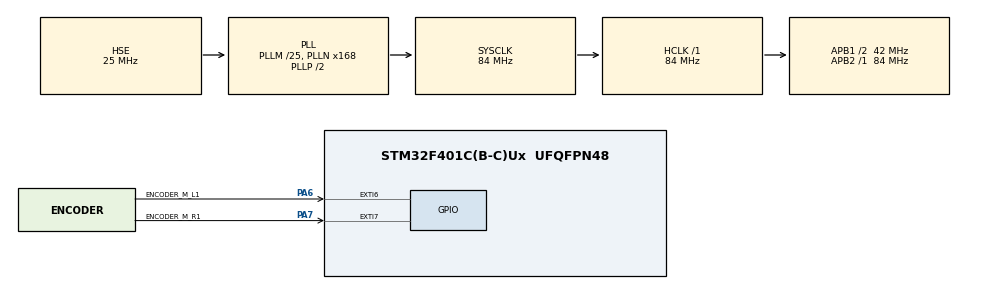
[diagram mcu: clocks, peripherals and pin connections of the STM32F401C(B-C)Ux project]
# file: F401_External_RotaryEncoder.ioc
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Mcu.Family=STM32F4
Mcu.Name=STM32F401C(B-C)Ux
Mcu.Package=UFQFPN48
NVIC.EXTI9_5_IRQn=true\:0\:0\:false\:false\:true\:true\:true\:true
NVIC.PriorityGroup=NVIC_PRIORITYGROUP_4
PA13.Mode=Serial_Wire
PA13.Signal=SYS_JTMS-SWDIO
PA14.Mode=Serial_Wire
PA14.Signal=SYS_JTCK-SWCLK
PA6.GPIO_Label=ENCODER_M_L1
PA6.GPIO_ModeDefaultEXTI=GPIO_MODE_IT_RISING_FALLING
PA6.GPIO_PuPd=GPIO_NOPULL
PA6.Signal=GPXTI6
PA7.GPIO_Label=ENCODER_M_R1
PA7.GPIO_ModeDefaultEXTI=GPIO_MODE_IT_RISING_FALLING
PA7.GPIO_PuPd=GPIO_NOPULL
PA7.Signal=GPXTI7
PH0\ -\ OSC_IN.Mode=HSE-External-Oscillator
PH0\ -\ OSC_IN.Signal=RCC_OSC_IN
PH1\ -\ OSC_OUT.Mode=HSE-External-Oscillator
PH1\ -\ OSC_OUT.Signal=RCC_OSC_OUT
ProjectManager.HeapSize=0x200
ProjectManager.StackSize=0x400
ProjectManager.TargetToolchain=STM32CubeIDE
RCC.48MHZClocksFreq_Value=42000000
RCC.AHBFreq_Value=84000000
RCC.APB1CLKDivider=RCC_HCLK_DIV2
RCC.APB1Freq_Value=42000000
RCC.APB1TimFreq_Value=84000000
RCC.APB2Freq_Value=84000000
RCC.APB2TimFreq_Value=84000000
RCC.CortexFreq_Value=84000000
RCC.HCLKFreq_Value=84000000
RCC.HSE_VALUE=25000000
RCC.HSI_VALUE=16000000
RCC.LSE_VALUE=32768
RCC.PLLM=25
RCC.PLLN=168
RCC.PLLSourceVirtual=RCC_PLLSOURCE_HSE
RCC.SYSCLKFreq_VALUE=84000000
RCC.SYSCLKSource=RCC_SYSCLKSOURCE_PLLCLK
RCC.VCOOutputFreq_Value=168000000
board=custom

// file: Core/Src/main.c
/* USER CODE BEGIN Header */
/**
 ******************************************************************************
 * @file           : main.c
 * @brief          : Main program body
 ******************************************************************************
 * @attention
 *
 * Copyright (c) 2024 STMicroelectronics.
 * All rights reserved.
 *
 * This software is licensed under terms that can be found in the LICENSE file
 * in the root directory of this software component.
 * If no LICENSE file comes with this software, it is provided AS-IS.
 *
 ******************************************************************************
 */
/* USER CODE END Header */
#include "main.h"
#include "gpio.h"

/* USER CODE BEGIN PV */

#define ENCODER_M_L1_Pin GPIO_PIN_6
#define ENCODER_M_R1_Pin GPIO_PIN_7
#define ENCODER_M_L1_GPIO_Port GPIOA
#define ENCODER_M_R1_GPIO_Port GPIOA
int encoder1;
int encoder2;
int counter = 0;
int last_encoder1 = 0;
int last_encoder2 = 0;

/* USER CODE END PV */

void SystemClock_Config(void);
/* USER CODE BEGIN PFP */

/* EXTERNAL ENTERRUPT */

void HAL_GPIO_EXTI_Callback(uint16_t GPIO_Pin) {
	if (GPIO_Pin == ENCODER_M_L1_Pin || ENCODER_M_R1_Pin) {
		encoder1 = HAL_GPIO_ReadPin(ENCODER_M_L1_GPIO_Port, ENCODER_M_L1_Pin);
		encoder2 = HAL_GPIO_ReadPin(ENCODER_M_R1_GPIO_Port, ENCODER_M_R1_Pin);
	}
}

/* USER CODE END PFP */

int main(void) {
	/* USER CODE BEGIN 1 */

	/* READ ENCODER */

	void encoder() {
		if (encoder1 != last_encoder1) {
			last_encoder1 = encoder1;
			if (encoder1 == 0) {
				if (encoder2 == 1) {
					counter++;
				} else {
					counter--;
				}
			} else {
				if (encoder2 == 0) {
					counter++;
				} else {
					counter--;
				}
			}
		}
		if (encoder2 != last_encoder2) {
			last_encoder2 = encoder2;
			if (encoder2 == 1) {
				if (encoder1 == 1) {
					counter++;
				} else {
					counter--;
				}
			} else {
				if (encoder1 == 0) {
					counter++;
				} else {
					counter--;
				}
			}
		}
	}

	/* USER CODE END 1 */

	/* MCU Configuration--------------------------------------------------------*/

	/* Reset of all peripherals, Initializes the Flash interface and the Systick. */
	HAL_Init();

	/* Configure the system clock */
	SystemClock_Config();

	/* Initialize all configured peripherals */
	MX_GPIO_Init();

	/* Infinite loop */
	while (1) {

		/* USER CODE BEGIN 3 */

		encoder();

	}
	/* USER CODE END 3 */
}

void SystemClock_Config(void) {
	RCC_OscInitTypeDef RCC_OscInitStruct = { 0 };
	RCC_ClkInitTypeDef RCC_ClkInitStruct = { 0 };

	/** Configure the main internal regulator output voltage
	 */
	__HAL_RCC_PWR_CLK_ENABLE();
	__HAL_PWR_VOLTAGESCALING_CONFIG(PWR_REGULATOR_VOLTAGE_SCALE2);

	/** Initializes the RCC Oscillators according to the specified parameters
	 * in the RCC_OscInitTypeDef structure.
	 */
	RCC_OscInitStruct.OscillatorType = RCC_OSCILLATORTYPE_HSE;
	RCC_OscInitStruct.HSEState = RCC_HSE_ON;
	RCC_OscInitStruct.PLL.PLLState = RCC_PLL_ON;
	RCC_OscInitStruct.PLL.PLLSource = RCC_PLLSOURCE_HSE;
	RCC_OscInitStruct.PLL.PLLM = 25;
	RCC_OscInitStruct.PLL.PLLN = 168;
	RCC_OscInitStruct.PLL.PLLP = RCC_PLLP_DIV2;
	RCC_OscInitStruct.PLL.PLLQ = 4;
	if (HAL_RCC_OscConfig(&RCC_OscInitStruct) != HAL_OK) {
		Error_Handler();
	}

	/** Initializes the CPU, AHB and APB buses clocks
	 */
	RCC_ClkInitStruct.ClockType = RCC_CLOCKTYPE_HCLK | RCC_CLOCKTYPE_SYSCLK
			| RCC_CLOCKTYPE_PCLK1 | RCC_CLOCKTYPE_PCLK2;
	RCC_ClkInitStruct.SYSCLKSource = RCC_SYSCLKSOURCE_PLLCLK;
	RCC_ClkInitStruct.AHBCLKDivider = RCC_SYSCLK_DIV1;
	RCC_ClkInitStruct.APB1CLKDivider = RCC_HCLK_DIV2;
	RCC_ClkInitStruct.APB2CLKDivider = RCC_HCLK_DIV1;

	if (HAL_RCC_ClockConfig(&RCC_ClkInitStruct, FLASH_LATENCY_2) != HAL_OK) {
		Error_Handler();
	}
}

void Error_Handler(void) {
	__disable_irq();
	while (1) {
	}
}
